# I2C register map
Vendor: Texas Instruments
Registers are 32-bit, access per field, no defined reset value unless marked. A register's access mark holds for its fields unless they carry their own. Offsets are as the file gives them; [hi:lo] are bit positions; 'fields as' and 'values as' point back to an identical list.

## I2C (part 2 of 2)
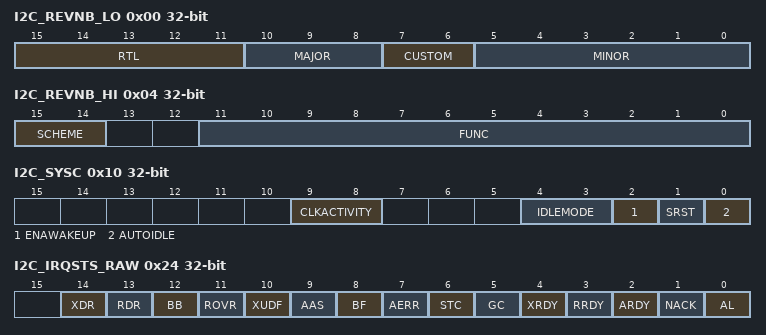
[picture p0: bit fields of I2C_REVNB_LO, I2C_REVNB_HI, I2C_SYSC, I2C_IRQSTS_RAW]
0x00 I2C_REVNB_LO ro — This read-only register contains the hard-coded revision number of the module. A write to this register has no effect. I2C controller with interrupt using interrupt vector register (I2C_IV) is revision 1.x. I2C controller with interrupt using status register bits (I2C_IRQSTATUS_RAW) is revision 2.x.
  [15:11] RTL — RTL version.
  [10:8] MAJOR — Major Revision. [[br]]This field changes when there is a major feature change. [[br]]This field does not change due to bug fix, or minor feature change.
  [7:6] CUSTOM — Indicates a special version for a particular device. [[br]]Consequence of use may avoid use of standard Chip Support Library (CSL) / Drivers. [[br]]0 if non-custom.
  [5:0] MINOR — Minor Revision This field changes when features are scaled up or down. [[br]]This field does not change due to bug fix, or major feature change.
0x04 I2C_REVNB_HI ro — A reset has no effect on the value returned.
  [15:14] SCHEME — Used to distinguish between old Scheme and current. [[br]]Spare bit to encode future schemes.
  [11:0] FUNC — Function: Indicates a software compatible module family
0x10 I2C_SYSC — This register allows controlling various parameters of the peripheral interface.
  [9:8] CLKACTIVITY rw — Clock Activity selection bits. [[br]]Those bits (one bit for each clock signal present on the boundary of the module) are set to 1 to disable external clock gating mechanism in Idle Mode. [[br]]Values after reset are low (for both 2 bits). [[br]]Note: If the System (functional) Clock is cut-off, the module will assert a WakeUp event when it asynchronously detects a Start Condition on the I2C Bus. [[br]]Note that in this case the first transfer will not be taken into account by the module (NACK will be detected by the external master).
    3=en_4_0x3 (Both clocks must be kept active); 2=en_3_0x2 (Only system clock must be kept active; Interface/OCP clock can be cut off); 1=en_2_0x1 (Only Interface/OCP clock must be kept active; system clock can be cut off); 0=en_1_0x0 (Both clocks can be cut off)
  [4:3] IDLEMODE rw — Idle Mode selection bits. [[br]]These two bits are used to select one of the idle mode operation mechanisms. [[br]]Value after reset is 00 (Force Idle).
    3=en_3_0x3 (Smart-idle wakeup.); 2=en_2_0x2 (Smart Idle mode); 1=en_1_0x1 (No Idle mode)
  [2] ENAWAKEUP rw — Enable Wakeup control bit. [[br]]When this bit is set to 1, the module enables its own wakeup mechanism. [[br]]Value after reset is low.
    1=en_2_0x1 (Wakeup mechanism is enabled); 0=en_1_0x0 (Wakeup mechanism is disabled)
  [1] SRST rw — SoftReset bit. [[br]]When this bit is set to 1, entire module is reset as for the hardware reset. [[br]]This bit is automatically cleared to 0 by the core and it is only reset by the hardware reset. [[br]]During reads, it always returns 0. [[br]]Value after reset is low. [[br]]
    1=en_2_0x1 (The module is reset); 0=en_1_0x0 (Normal mode)
  [0] AUTOIDLE rw — Autoidle bit. [[br]]When this bit is set to 1, the module activates its own idle mode mechanism. [[br]]By evaluating its internal state, the module can decide to gate part of his internal clock tree in order to improve the overall power consumption. [[br]]Value after reset is high.
    1=en_2_0x1 (Auto Idle mechanism is enabled); 0=en_1_0x0 (Auto Idle mechanism is disabled)
0x24 I2C_IRQSTS_RAW — This register provides core status information for interrupt handling, showing all active events (enabled and not enabled). The fields are read-write. Writing a 1 to a bit will set it to 1, that is, trigger the IRQ (mostly for debug). Writing a 0 will have no effect, that is, the register value will not be modified. Only enabled, active events will trigger an actual interrupt request on the IRQ output line.
  [14] XDR rw — Transmit draining IRQ status. [[br]]I2C Master Transmit mode only. [[br]]This read/clear only bit is set to 1 when the module is configured as a master transmitter, the TX FIFO level is below the configured threshold (TXTRSH) and the amount of data still to be transferred is less than TXTRSH. [[br]]When this bit is set to 1 by the core, CPU must read the I2C_BUFSTAT.TXSTAT register in order to check the amount of data that need to be written in the TX FIFO. [[br]]Then, according to the mode set (DMA or interrupt), the CPU can enable the DMA draining feature of the DMA controller with the number of data bytes to be transferred (I2C_BUFSTAT.TXSTAT), or generate write data accesses according to this value (IRQ mode). [[br]]The interrupt needs to be cleared after the DMA controller was reconfigured (if DMA mode enabled), or before generating data accesses to the FIFO (if IRQ mode enabled). [[br]]If the corresponding interrupt was enabled, an interrupt is signaled to the local host. [[br]]The CPU can also poll this bit. [[br]]For more details about TDR generation, refer to the FIFO Management subsection. [[br]]The CPU can only clear this bit by writing a 1 into the I2C_IRQSTS register. [[br]]A write 0 has no effect. [[br]]Value after reset is low. [[br]]
    1=en_2_0x1 (Transmit draining enabled); 0=en_1_0x0 (Transmit draining inactive)
  [13] RDR rw — Receive draining IRQ status. [[br]]I2C Receive mode only. [[br]]This read/clear only bit is set to 1 when the module is configured as a receiver, a stop condition was received on the bus and the RX FIFO level is below the configured threshold (RXTRSH). [[br]]When this bit is set to 1 by the core, CPU must read the I2C_BUFSTAT.RXSTAT register in order to check the amount of data left to be transferred from the FIFO. [[br]]Then, according to the mode set (DMA or interrupt), the CPU needs to enable the draining feature of the DMA controller with the number of data bytes to be transferred (I2C_BUFSTAT.RXSTAT), or generate read data accesses according to this value (IRQ mode). [[br]]The interrupt needs to be cleared after the DMA controller was reconfigured (if DMA mode enabled), or before generating data accesses to the FIFO (if IRQ mode enabled). [[br]]If the corresponding interrupt was enabled, an interrupt is signaled to the local host. [[br]]The CPU can also poll this bit. [[br]]For more details about RDR generation, refer to the FIFO Management subsection. [[br]]The CPU can only clear this bit by writing a 1 into the I2C_IRQSTS register. [[br]]A write 0 has no effect. [[br]]Value after reset is low. [[br]]
    1=en_2_0x1 (Receive draining enabled); 0=en_1_0x0 (Receive draining inactive)
  [12] BB ro — This read-only bit indicates the state of the serial bus. [[br]]In slave mode, on reception of a start condition, the device sets BB to 1. [[br]]BB is cleared to 0 after reception of a stop condition. [[br]]In master mode, the software controls BB. [[br]]To start a transmission with a start condition, MST, TRX, and STT must be set to 1 in the I2C_CON register. [[br]]To end a transmission with a stop condition, STP must be set to 1 in the I2C_CON register. [[br]]When BB = 1 and STT = 1, a restart condition is generated. [[br]]Value after reset is low. [[br]]
    1=en_2_0x1 (Bus is occupied); 0=en_1_0x0 (Bus is free)
  [11] ROVR rw — Receive overrun status. [[br]]Writing into this bit has no effect. [[br]]I2C receive mode only. [[br]]This read-only bit indicates whether the receiver has experienced overrun. [[br]]Overrun occurs when the shift register is full and the receive FIFO is full. [[br]]An overrun condition does not result in a data loss[[br]] the peripheral is just holding the bus (low on SCL) and prevents other bytes from being received. [[br]]ROVR is set to 1 when the I2C has recognized an overrun. [[br]]ROVR is clear when reading I2C_DATA register, or when resetting the I2C (I2C_CON:I2C_EN = 0). [[br]]Value after reset is low. [[br]]
    1=en_2_0x1 (Receiver overrun); 0=en_1_0x0 (Normal operation)
  [10] XUDF rw — Transmit underflow status. [[br]]Writing into this bit has no effect. [[br]]I2C transmit mode only. [[br]]This read-only bit indicates whether the transmitter has experienced underflow. [[br]]In master transmit mode, underflow occurs when the shift register is empty, the transmit FIFO is empty, and there are still some bytes to transmit (DCOUNT 0). [[br]]In slave transmit mode, underflow occurs when the shift register is empty, the transmit FIFO is empty, and there are still some bytes to transmit (read request from external I2C master). [[br]]XUDF is set to 1 when the I2C has recognized an underflow. [[br]]The core holds the line till the underflow cause has disappeared. [[br]]XUDF is clear when writing I2C_DATA register or resetting the I2C (I2C_CON:I2C_EN = 0). [[br]]Value after reset is low.
    1=en_2_0x1 (Transmit underflow); 0=en_1_0x0 (Normal operation)
  [9] AAS rw — Address recognized as slave IRQ status. [[br]]I2C mode only. [[br]]This read only bit is set to 1 by the device when it has recognized its own slave address (or one of the alternative own addresses), or an address of all zeros (8 bits). [[br]]When this bit is set to 1 by the core, an interrupt is signaled to the local host if the interrupt was enabled. [[br]]This bit can be cleared in 2 ways: One way is if the interrupt was enabled, it will be cleared by writing 1 into the I2C_IRQSTS register (writing 0 has no effect). [[br]]The other way is if the interrupt was not enabled, the AAS bit is reset to 0 by restart or stop. [[br]]Value after reset is low.
    1=en_2_0x1 (Address recognized); 0=en_1_0x0 (No action)
  [8] BF rw — I2C mode only. [[br]]This read only bit is set to 1 by the device when the I2C bus became free (after a transfer is ended on the bus stop condition detected). [[br]]This interrupt informs the Local Host that it can initiate its own I2C transfer on the bus. [[br]]When this bit is set to 1 by the core, an interrupt is signaled to the local host if the interrupt was enabled. [[br]]The CPU can only clear this bit by writing a 1 into the I2C_IRQSTS register. [[br]]Writing 0 has no effect. [[br]]Value after reset is low.
    1=en_2_0x1 (Bus Free); 0=en_1_0x0 (No action)
  [7] AERR rw — Access Error IRQ status. [[br]]I2C mode only. [[br]]This read/clear only bit is set to 1 by the device if an Interface/OCP write access is performed to I2C_DATA while the TX FIFO is full or if an Interface/OCP read access is performed to the I2C_DATA while the RX FIFO is empty. [[br]]Note that, when the RX FIFO is empty, a read access will return to the previous read data value. [[br]]When the TX FIFO is full, a write access is ignored. [[br]]In both events, the FIFO pointers will not be updated. [[br]]When this bit is set to 1 by the core, an interrupt is signaled to the local host if the interrupt was enabled. [[br]]The CPU can only clear this bit by writing a 1 into the I2C_IRQSTS register. [[br]]Writing 0 has no effect. [[br]]Value after reset is low. [[br]]
    1=en_2_0x1 (Access Error); 0=en_1_0x0 (No action)
  [6] STC rw — Start Condition IRQ status. [[br]]I2C mode only. [[br]]This read/clear only bit is set to 1 by the device if previously the module was in idle mode and a start condition was asynchronously detected on the I2C Bus and signalized with an Wakeup (if the I2C_SYSC.ClockActivity allows the system clock to be cut-off). [[br]]When the Active Mode will be restored and the interrupt generated, this bit will indicate the reason of the wakeup. [[br]]Note [[br]]1: The corresponding interrupt for this bit should be enabled only if the module was configured to allow the possibility of cutting-off the system clock while in Idle State (I2C_SYSC.ClockActivity = 00 or 01). [[br]]Note [[br]]2: The first transfer (corresponding to the detected start condition) will be lost (not taken into account by the module) and it will be used only for generating the WakeUp enable for restoring the Active Mode of the module. [[br]]On the I2C line, the external master which generated the transfer will detect this behavior as a not acknowledge to the address phase and will possibly restart the transfer. [[br]]The CPU can only clear this bit by writing a 1 into the I2C_IRQSTS register. [[br]]Writing 0 has no effect. [[br]]Value after reset is low.
    1=en_2_0x1 (Start Condition detected); 0=en_1_0x0 (No action)
  [5] GC rw — General call IRQ status. [[br]]Set to '1' by core when General call address detected and interrupt signaled to MPUSS. [[br]]Write '1' to clear. [[br]]I2C mode only. [[br]]This read/clear only bit is set to 1 by the device if it detects the address of all zeros (8 bits) (general call). [[br]]When this bit is set to 1 by the core, an interrupt is signaled to the local host if the interrupt was enabled. [[br]]The CPU can only clear this bit by writing a 1 into the I2C_IRQSTS register. [[br]]Writing 0 has no effect. [[br]]Note: When this bit is set to 1, AAS also reads as 1. [[br]]Value after reset is low. [[br]]
    1=en_2_0x1 (General call address detected); 0=en_1_0x0 (No general call detected)
  [4] XRDY rw — Transmit data ready IRQ status. [[br]]Set to '1' by core when transmitter and when new data is requested. [[br]]When set to '1' by core, an interrupt is signaled to MPUSS. [[br]]Write '1' to clear. [[br]]Transmit mode only (I2C mode). [[br]]This read/clear only bit (XRDY) is set to 1 when the I2C peripheral is a master or slave transmitter, the CPU needs to send data through the I2C bus, and the module (transmitter) requires new data to be served. [[br]]Note that a master transmitter requests new data if the FIFO TX level is below the threshold (TXTRSH) and the required amount of data remained to be transmitted (I2C_BUFSTAT.TXSTAT) is greater than the threshold. [[br]]A slave transmitter requests new data when the FIFO TX level is below the threshold (if TXTRSH > 1), or anytime there is a read request from external master (for each acknowledge received from the master), if TXTRSH = 1. [[br]]When this bit is set to 1 by the core, an interrupt is signaled to the local host if the interrupt was enabled. [[br]]The CPU can also poll this bit (refer to the FIFO Management subsection for details about XRDY generation). [[br]]The CPU can only clear this bit by writing a 1 into the I2C_IRQSTS register. [[br]]Writing 0 has no effect. [[br]]Note: If the DMA transmit mode is enabled (I2C_BUF.XDMA_EN is set, together with I2C_DMATXEN_SET), this bit is forced to 0 and no interrupt will be generated[[br]] instead, a DMA TX request to the main DMA controller of the system is generated. [[br]]Value after reset is low. [[br]]
    1=en_2_0x1 (Transmit data ready); 0=en_1_0x0 (Transmission ongoing)
  [3] RRDY rw — Receive mode only (I2C mode). [[br]]This read/clear only RRDY is set to 1 when the RX FIFO level is above the configured threshold (RXTRSH). [[br]]When this bit is set to 1 by the core, CPU is able to read new data from the I2C_DATA register. [[br]]If the corresponding interrupt was enabled, an interrupt is signaled to the local host. [[br]]The CPU to read the received data in I2C_DATA register can also poll this bit (refer to the FIFO Management subsection for details about RRDY generation). [[br]]The CPU can only clear this bit by writing a 1 into the I2C_IRQSTS register. [[br]]A write 0 has no effect. [[br]]If the DMA receive mode is enabled (I2C_BUF.RDMA_EN is set, together with I2C_DMARXENABLE_SET), this bit is forced to 0 and no interrupt will be generated[[br]] instead a DMA RX request to the main DMA controller of the system is generated. [[br]]Value after reset is low. [[br]]
    1=en_2_0x1 (Receive data ready for read (RX FIFO threshold reached)); 0=en_1_0x0 (Receive FIFO threshold not reached)
  [2] ARDY rw — I2C mode only. [[br]]This read/clear only bit, when set to 1, indicates that the previously programmed data and command (receive or transmit, master or slave) has been performed and status bit has been updated. [[br]]The CPU uses this flag to let it know that the I2C registers are ready to be accessed again. [[br]]The CPU can only clear this bit by writing a 1 into the I2C_IRQSTS register. [[br]]A write 0 has no effect. [[br]]Mode: I2C Master transmit, Others: STP = 1, ARDY Set Condition: DCOUNT = 0. [[br]]Mode: I2C Master receive, Others: STP = 1, ARDY Set Condition: DCOUNT = 0 and receiver FIFO empty Mode: I2C Master transmit, Others: STP = 0, ARDY Set Condition: DCOUNT passed 0 Mode: I2C Master receive, Others: STP = 0, ARDY Set Condition: DCOUNT passed 0 and receiver FIFO empty Mode: I2C Master transmit, Others: n/a, ARDY Set Condition: Stop or restart condition received from master Mode: I2C Slave receive, Others: n/a, ARDY Set Condition: Stop or restart condition and receiver FIFO empty Value after reset is low. [[br]]
    1=en_2_0x1 (Access ready); 0=en_1_0x0 (No action)
  [1] NACK rw — No acknowledgment IRQ status. [[br]]Bit is set when No Acknowledge has been received, an interrupt is signaled to MPUSS. [[br]]Write '1' to clear this bit. [[br]]I2C mode only. [[br]]The read/clear only No Acknowledge flag bit is set when the hardware detects No Acknowledge has been received. [[br]]When a NACK event occurs on the bus, this bit is set to 1, the core automatically ends the transfer and clears the MST/STP bits in the I2C_CON register and the I2C becomes a slave. [[br]]Clearing the FIFOs from remaining data might be required. [[br]]The CPU can only clear this bit by writing a 1 into the I2C_IRQSTS register. [[br]]Writing 0 has no effect. [[br]]Value after reset is low.
    1=en_2_0x1 (Not Acknowledge detected); 0=en_1_0x0 (Normal operation)
  [0] AL rw — Arbitration lost IRQ status. [[br]]This bit is automatically set by the hardware when it loses the Arbitration in master transmit mode, an interrupt is signaled to MPUSS. [[br]]During reads, it always returns 0. [[br]]I2C mode only. [[br]]The read/clear only Arbitration Lost flag bit is set to 1 when the device (configured in master mode) detects it has lost an arbitration (in Address Phase). [[br]]This happens when two or more masters initiate a transfer on the I2C bus almost simultaneously or when the I2C attempts to start a transfer while BB (bus busy) is 1. [[br]]When this is set to 1 due to arbitration lost, the core automatically clears the MST/STP bits in the I2C_CON register and the I2C becomes a slave receiver. [[br]]The CPU can only clear this bit by writing a 1 to the I2C_IRQSTS register. [[br]]Writing 0 has no effect. [[br]]Value after reset is low. [[br]]
    1=en_2_0x1 (Arbitration lost detected); 0=en_1_0x0 (Normal operation)
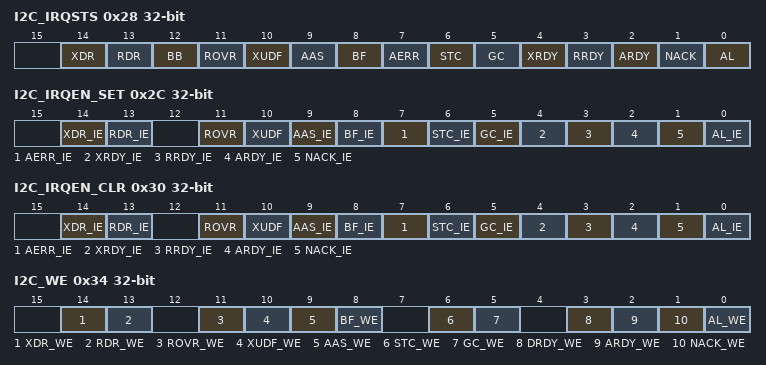
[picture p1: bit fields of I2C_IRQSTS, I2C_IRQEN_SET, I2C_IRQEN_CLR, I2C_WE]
0x28 I2C_IRQSTS — This register provides core status information for interrupt handling, showing all active and enabled events and masking the others. The fields are read-write. Writing a 1 to a bit will clear it to 0, that is, clear the IRQ. Writing a 0 will have no effect, that is, the register value will not be modified. Only enabled, active events will trigger an actual interrupt request on the IRQ output line. For all the internal fields of the I2C_IRQSTATUS register, the descriptions given in the I2C_IRQSTATUS_RAW subsection are valid.
  [14] XDR rw — Transmit draining IRQ enabled status.
    values as I2C_IRQSTS_RAW.XDR
  [13] RDR rw — Receive draining IRQ enabled status.
    values as I2C_IRQSTS_RAW.RDR
  [12] BB rw — Bus busy enabled status. [[br]]Writing into this bit has no effect.
    1=en_2_0x1 (Bus is occupied); 0=en_1_0x0 (Bus is free)
  [11] ROVR rw — Receive overrun enabled status. [[br]]Writing into this bit has no effect.
    1=en_2_0x1 (Receiver overrun); 0=en_1_0x0 (Normal operation)
  [10] XUDF rw — Transmit underflow enabled status. [[br]]Writing into this bit has no effect.
    values as I2C_IRQSTS_RAW.XUDF
  [9] AAS rw — Address recognized as slave IRQ enabled status.
    1=en_2_0x1 (Address recognized); 0=en_1_0x0 (No action)
  [8] BF rw — Bus Free IRQ enabled status.
    1=en_2_0x1 (Bus free); 0=en_1_0x0 (No action)
  [7] AERR rw — Access Error IRQ enabled status.
    1=en_2_0x1 (Access error); 0=en_1_0x0 (No action)
  [6] STC rw — Start Condition IRQ enabled status.
    1=en_2_0x1 (Start condition detected); 0=en_1_0x0 (No action)
  [5] GC rw — General call IRQ enabled status. [[br]]Set to '1' by core when General call address detected and interrupt signaled to MPUSS. [[br]]Write '1' to clear.
    values as I2C_IRQSTS_RAW.GC
  [4] XRDY rw — Transmit data ready IRQ enabled status. [[br]]Set to '1' by core when transmitter and when new data is requested. [[br]]When set to '1' by core, an interrupt is signaled to MPUSS. [[br]]Write '1' to clear. [[br]]
    values as I2C_IRQSTS_RAW.XRDY
  [3] RRDY rw — Receive data ready IRQ enabled status. [[br]]Set to '1' by core when receiver mode, a new data is able to be read. [[br]]When set to '1' by core, an interrupt is signaled to MPUSS. [[br]]Write '1' to clear. [[br]]
    1=en_2_0x1 (Receive data available); 0=en_1_0x0 (No data available)
  [2] ARDY rw — Register access ready IRQ enabled status. [[br]]When set to '1' it indicates that previous access has been performed and registers are ready to be accessed again. [[br]]An interrupt is signaled to MPUSS. [[br]]Write '1' to clear. [[br]]
    1=en_2_0x1 (Access ready); 0=en_1_0x0 (Module busy)
  [1] NACK rw — No acknowledgment IRQ enabled status. [[br]]Bit is set when No Acknowledge has been received, an interrupt is signaled to MPUSS. [[br]]Write '1' to clear this bit.
    values as I2C_IRQSTS_RAW.NACK
  [0] AL rw — Arbitration lost IRQ enabled status. [[br]]This bit is automatically set by the hardware when it loses the Arbitration in master transmit mode, an interrupt is signaled to MPUSS. [[br]]During reads, it always returns 0. [[br]]
    values as I2C_IRQSTS_RAW.AL
0x2C I2C_IRQEN_SET — All 1-bit fields enable a specific interrupt event to trigger an interrupt request. Writing a 1 to a bit will enable the field. Writing a 0 will have no effect, that is, the register value will not be modified. For all the internal fields of the I2C_IRQENABLE_SET register, the descriptions given in the I2C_IRQSTATUS_RAW subsection are valid.
  [14] XDR_IE rw — Transmit draining interrupt enable set. [[br]]Mask or unmask the interrupt signaled by bit in I2C_STAT[XDR].
    1=en_2_0x1 (Transmit draining interrupt enabled); 0=en_1_0x0 (Transmit draining interrupt disabled)
  [13] RDR_IE rw — Receive draining interrupt enable set. [[br]]Mask or unmask the interrupt signaled by bit in I2C_STAT[RDR].
    1=en_2_0x1 (Receive draining interrupt enabled); 0=en_1_0x0 (Receive draining interrupt disabled)
  [11] ROVR rw — Receive overrun enable set.
    1=en_2_0x1 (Receive draining interrupt enabled); 0=en_1_0x0 (Receive overrun interrupt disabled)
  [10] XUDF rw — Transmit underflow enable set.
    1=en_2_0x1 (Transmit underflow interrupt enabled); 0=en_1_0x0 (Transmit underflow interrupt disabled)
  [9] AAS_IE rw — Addressed as slave interrupt enable set. [[br]]Mask or unmask the interrupt signaled by bit in I2C_STAT[AAS].
    1=en_2_0x1 (Addressed as slave interrupt enabled); 0=en_1_0x0 (Addressed as slave interrupt disabled)
  [8] BF_IE rw — Bus free interrupt enable set. [[br]]Mask or unmask the interrupt signaled by bit in I2C_STAT[BF].
    1=en_2_0x1 (Bus free interrupt enabled); 0=en_1_0x0 (Bus free interrupt disabled)
  [7] AERR_IE rw — Access error interrupt enable set. [[br]]Mask or unmask the interrupt signaled by bit in I2C_STAT[AERR].
    1=en_2_0x1 (Access error interrupt enabled); 0=en_1_0x0 (Access error interrupt disabled)
  [6] STC_IE rw — Start condition interrupt enable set. [[br]]Mask or unmask the interrupt signaled by bit in I2C_STAT[STC].
    1=en_2_0x1 (Start condition interrupt enabled); 0=en_1_0x0 (Start condition interrupt disabled)
  [5] GC_IE rw — General call interrupt enable set. [[br]]Mask or unmask the interrupt signaled by bit in I2C_STAT[GC].
    1=en_2_0x1 (General call interrupt enabled); 0=en_1_0x0 (General call interrupt disabled)
  [4] XRDY_IE rw — Transmit data ready interrupt enable set. [[br]]Mask or unmask the interrupt signaled by bit in I2C_STAT[XRDY].
    1=en_2_0x1 (Transmit data ready interrupt enabled); 0=en_1_0x0 (Transmit data ready interrupt disabled)
  [3] RRDY_IE rw — Receive data ready interrupt enable set. [[br]]Mask or unmask the interrupt signaled by bit in I2C_STAT[RRDY].
    1=en_2_0x1 (Receive data ready interrupt enabled); 0=en_1_0x0 (Receive data ready interrupt disabled)
  [2] ARDY_IE rw — Register access ready interrupt enable set. [[br]]Mask or unmask the interrupt signaled by bit in I2C_STAT[ARDY].
    1=en_2_0x1 (Register access ready interrupt enabled); 0=en_1_0x0 (Register access ready interrupt disabled)
  [1] NACK_IE rw — No acknowledgment interrupt enable set. [[br]]Mask or unmask the interrupt signaled by bit in I2C_STAT[NACK].
    1=en_2_0x1 (Not Acknowledge interrupt enabled); 0=en_1_0x0 (Not Acknowledge interrupt disabled)
  [0] AL_IE rw — Arbitration lost interrupt enable set. [[br]]Mask or unmask the interrupt signaled by bit in I2C_STAT[AL].
    1=en_2_0x1 (Arbitration lost interrupt enabled); 0=en_1_0x0 (Arbitration lost interrupt disabled)
0x30 I2C_IRQEN_CLR — All 1-bit fields clear a specific interrupt event. Writing a 1 to a bit will disable the interrupt field. Writing a 0 will have no effect, that is, the register value will not be modified. For all the internal fields of the I2C_IRQENABLE_CLR register, the descriptions given in the I2C_IRQSTATUS_RAW subsection are valid.
  [14] XDR_IE rw — Transmit draining interrupt enable clear. [[br]]Mask or unmask the interrupt signaled by bit in I2C_STAT[XDR].
    values as I2C_IRQEN_SET.XDR_IE
  [13] RDR_IE rw — Receive draining interrupt enable clear. [[br]]Mask or unmask the interrupt signaled by bit in I2C_STAT[RDR].
    values as I2C_IRQEN_SET.RDR_IE
  [11] ROVR rw — Receive overrun enable clear.
    values as I2C_IRQEN_SET.ROVR
  [10] XUDF rw — Transmit underflow enable clear.
    values as I2C_IRQEN_SET.XUDF
  [9] AAS_IE rw — Addressed as slave interrupt enable clear. [[br]]Mask or unmask the interrupt signaled by bit in I2C_STAT[AAS].
    values as I2C_IRQEN_SET.AAS_IE
  [8] BF_IE rw — Bus Free interrupt enable clear. [[br]]Mask or unmask the interrupt signaled by bit in I2C_STAT[BF].
    values as I2C_IRQEN_SET.BF_IE
  [7] AERR_IE rw — Access error interrupt enable clear. [[br]]Mask or unmask the interrupt signaled by bit in I2C_STAT[AERR].
    values as I2C_IRQEN_SET.AERR_IE
  [6] STC_IE rw — Start condition interrupt enable clear. [[br]]Mask or unmask the interrupt signaled by bit in I2C_STAT[STC].
    values as I2C_IRQEN_SET.STC_IE
  [5] GC_IE rw — General call interrupt enable clear. [[br]]Mask or unmask the interrupt signaled by bit in I2C_STAT[GC].
    values as I2C_IRQEN_SET.GC_IE
  [4] XRDY_IE rw — Transmit data ready interrupt enable clear. [[br]]Mask or unmask the interrupt signaled by bit in I2C_STAT[XRDY].
    values as I2C_IRQEN_SET.XRDY_IE
  [3] RRDY_IE rw — Receive data ready interrupt enable set. [[br]]Mask or unmask the interrupt signaled by bit in I2C_STAT[RRDY]
    values as I2C_IRQEN_SET.RRDY_IE
  [2] ARDY_IE rw — Register access ready interrupt enable clear. [[br]]Mask or unmask the interrupt signaled by bit in I2C_STAT[ARDY].
    values as I2C_IRQEN_SET.ARDY_IE
  [1] NACK_IE rw — No acknowledgment interrupt enable clear. [[br]]Mask or unmask the interrupt signaled by bit in I2C_STAT[NACK].
    values as I2C_IRQEN_SET.NACK_IE
  [0] AL_IE rw — Arbitration lost interrupt enable clear. [[br]]Mask or unmask the interrupt signaled by bit in I2C_STAT[AL].
    values as I2C_IRQEN_SET.AL_IE
0x34 I2C_WE — Every 1-bit field in the I2C_WE register enables a specific (synchronous) IRQ request source to generate an asynchronous wakeup (on the appropriate swakeup line). When a bit location is set to 1 by the local host, a wakeup is signaled to the local host if the corresponding event is captured by the core of the I2C controller. Value after reset is low (all bits). There is no need for an Access Error WakeUp event, since this event occurs only when the module is in Active Mode (for Interface/OCP accesses to FIFO) and is signaled by an interrupt. With the exception of Start Condition WakeUp, which is asynchronously detected when the Functional clock is turned-off, all the other WakeUp events require the Functional (System) clock to be enabled.
  [14] XDR_WE rw — Transmit draining wakeup enable. [[br]]This read/write bit is used to enable or disable wakeup signal generation when I2C module is in idle mode, the TX FIFO level is below the threshold and the amount of data left to be transferred is less than TXTRSH value. [[br]]This allows for the module to inform the CPU that it can check the amount of data to be written to the FIFO.
    1=en_2_0x1 (Transmit draining wakeup enabled); 0=en_1_0x0 (Transmit draining wakeup disabled)
  [13] RDR_WE rw — Receive draining wakeup enable. [[br]]This read/write bit is used to enable or disable wakeup signal generation when I2C is in idle mode, configured as a receiver, and it has detected a stop condition on the bus but the RX FIFO threshold is not reached (but the FIFO is not empty). [[br]]This allows for the module to inform the CPU that it can check the amount of data to be transferred from the FIFO.
    1=en_2_0x1 (Receive draining wakeup enabled); 0=en_1_0x0 (Receive draining wakeup disabled)
  [11] ROVR_WE rw — Receive overrun wakeup enable
    1=en_2_0x1 (Receive overrun wakeup enabled); 0=en_1_0x0 (Receive overrun wakeup disabled)
  [10] XUDF_WE rw — Transmit underflow wakeup enable
    1=en_2_0x1 (Transmit underflow wakeup enabled); 0=en_1_0x0 (Transmit underflow wakeup disabled)
  [9] AAS_WE rw — Address as slave IRQ wakeup enable. [[br]]This read/write bit is used to enable or disable wakeup signal generation when I2C module is in idle mode, and external master addresses the I2C module as a slave. [[br]]This allows for the module to inform the CPU that it can check which of the own addresses was used by the external master to access the I2C core.
    1=en_2_0x1 (Addressed as slave wakeup enabled); 0=en_1_0x0 (Addressed as slave wakeup disabled)
  [8] BF_WE rw — Bus free IRQ wakeup enable. [[br]]This read/write bit is used to enable or disable wakeup signal generation when I2C module is in idle mode and the I2C bus became free. [[br]]This allows for the module to inform the CPU that it can initiate its own transfer on the I2C line.
    1=en_2_0x1 (Bus Free wakeup enabled); 0=en_1_0x0 (Bus Free wakeup disabled)
  [6] STC_WE rw — Start condition IRQ wakeup set. [[br]]This read/write bit is used to enable or disable wakeup signal generation when I2C module is in idle mode (with the functional clock inactive) and a possible start condition is detected on the I2C line. [[br]]The STC WakeUp is generated only if the I2C_SYSC.ClockActivity field indicates that the functional clock can be disabled. [[br]]Note that if the functional clock is not active, the start condition is asynchronously detected (no filtering and synchronization is used). [[br]]For this reason, it is possible that the signalized start condition to be a glitch. [[br]]If the functional clock cannot be disabled (I2C_SYSC.ClockActivity = 10 or 11), the programmer should not enable this wakeup, since the module has other synchronously detected WakeUp event that might be used to exit from idle mode, only if the detected transfer is accessing the I2C module.
    1=en_2_0x1 (Start condition wakeup enabled); 0=en_1_0x0 (Start condition wakeup disabled)
  [5] GC_WE rw — General call IRQ wakeup enable. [[br]]This read/write bit is used to enable or disable wakeup signal generation when I2C module is in idle mode and a general call is received on I2C line.
    1=en_2_0x1 (General call wakeup enabled); 0=en_1_0x0 (General call wakeup disabled)
  [3] DRDY_WE rw — Receive/Transmit data ready IRQ wakeup enable. [[br]]This read/write bit is used to enable or disable wakeup signal generation when I2C module is involved into a long transfer and no more registers accesses are performed on the interface (for example module are set in F/S I2C master transmitter mode and FIFO is full). [[br]]If in the middle of such a transaction, the FIFO buffer needs more data to be transferred, CPU must be informed to write (in case of transmitter mode) or read (if receiver mode) in/from the FIFO.
    1=en_2_0x1 (Transmit/receive data ready wakeup enabled); 0=en_1_0x0 (Transmit/receive data ready wakeup disabled)
  [2] ARDY_WE rw — Register access ready IRQ wakeup enable. [[br]]This read/write bit is used to enable or disable wakeup signal generation when I2C module is involved into a long transfer and no more registers accesses are performed on the interface (for example the module is set in F/S I2C master transmitter mode and FIFO is full). [[br]]If the current transaction is finished, the module needs to inform CPU about transmission completion.
    1=en_2_0x1 (Register access ready wakeup enabled); 0=en_1_0x0 (Register access ready wakeup disabled)
  [1] NACK_WE rw — No acknowledgment IRQ wakeup enable. [[br]]This read/write bit is used to enable or disable wakeup signal generation when I2C module is involved into a long transfer and no more registers accesses are performed on the interface (for example the module is set in F/S I2C master transmitter mode and FIFO is full). [[br]]If in the middle of such of a transaction a Not Acknowledgment event is raised, the module needs to inform CPU about transmission error.
    1=en_2_0x1 (Not Acknowledge wakeup enabled); 0=en_1_0x0 (Not Acknowledge wakeup disabled)
  [0] AL_WE rw — Arbitration lost IRQ wakeup enable. [[br]]This read/write bit is used to enable or disable wakeup signal generation when I2C module is configured as a master and it loses the arbitration. [[br]]This wake up is very useful when the module is configured as a master transmitter, all the necessary data is provided in the FIFO Tx, STT is enabled and the module enters in Idle Mode. [[br]]If the module loses the arbitration, an Arbitration Lost event is raised and the module needs to inform CPU about transmission error. [[br]]Note: The AL wakeup must be enabled only for multimaster communication. [[br]]If the AL_WE is not enabled and the scenario described above occurs, the module will not be able to inform the CPU about the state of the transfer and it will be blocked in an undetermined state.
    1=en_2_0x1 (Arbitration lost wakeup enabled); 0=en_1_0x0 (Arbitration lost wakeup disabled)
